# jbr_MDR1901VC1T register map
Registers are 32-bit, access not given, no defined reset value unless marked. A register's access mark holds for its fields unless they carry their own. Addresses are absolute; registers are grouped by the start of their names; [hi:lo] are bit positions; {n}, {i} and the like mark numbered series.

## UART3
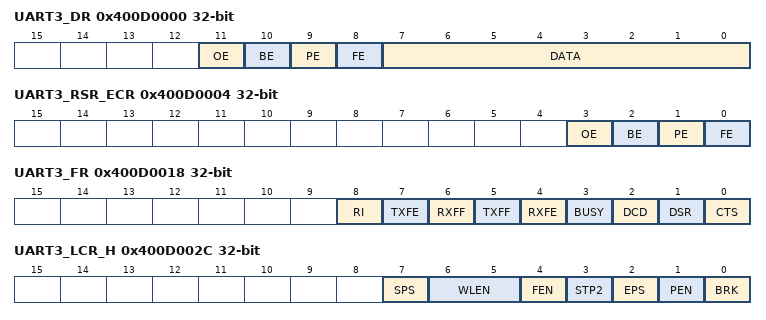
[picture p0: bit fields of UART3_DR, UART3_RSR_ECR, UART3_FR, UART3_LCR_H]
0x400D0000 UART3_DR
  [11] OE, [10] BE, [9] PE, [8] FE, [7:0] DATA
0x400D0004 UART3_RSR_ECR
  [3] OE, [2] BE, [1] PE, [0] FE
0x400D0018 UART3_FR
  [8] RI, [7] TXFE, [6] RXFF, [5] TXFF, [4] RXFE, [3] BUSY, [2] DCD, [1] DSR, [0] CTS
0x400D0020 UART3_ILPR
  [7:0] ILPDVSR
0x400D0024 UART3_IBRD
  [15:0] BAUD_DIVINT
0x400D0028 UART3_FBRD
  [5:0] BAUD_DIVFRAC
0x400D002C UART3_LCR_H
  [7] SPS, [6:5] WLEN, [4] FEN, [3] STP2, [2] EPS, [1] PEN, [0] BRK
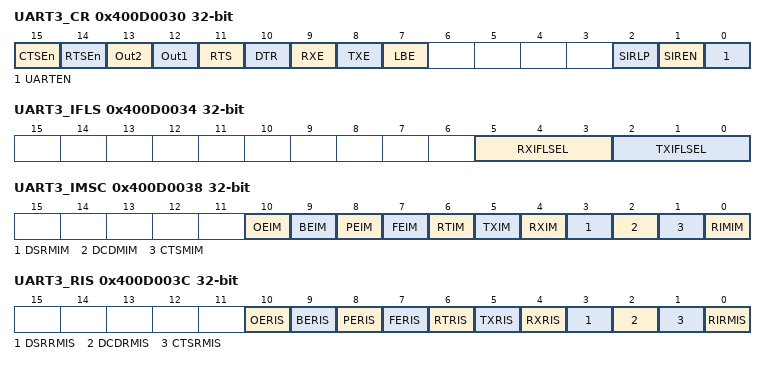
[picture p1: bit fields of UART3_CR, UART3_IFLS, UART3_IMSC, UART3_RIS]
0x400D0030 UART3_CR
  [15] CTSEn, [14] RTSEn, [13] Out2, [12] Out1, [11] RTS, [10] DTR, [9] RXE, [8] TXE, [7] LBE, [2] SIRLP, [1] SIREN, [0] UARTEN
0x400D0034 UART3_IFLS
  [5:3] RXIFLSEL, [2:0] TXIFLSEL
0x400D0038 UART3_IMSC
  [10] OEIM, [9] BEIM, [8] PEIM, [7] FEIM, [6] RTIM, [5] TXIM, [4] RXIM, [3] DSRMIM, [2] DCDMIM, [1] CTSMIM, [0] RIMIM
0x400D003C UART3_RIS
  [10] OERIS, [9] BERIS, [8] PERIS, [7] FERIS, [6] RTRIS, [5] TXRIS, [4] RXRIS, [3] DSRRMIS, [2] DCDRMIS, [1] CTSRMIS, [0] RIRMIS
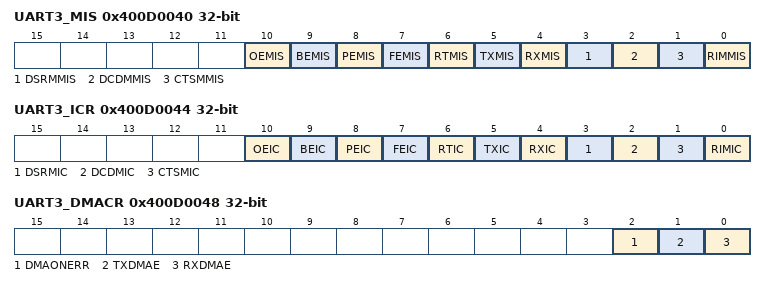
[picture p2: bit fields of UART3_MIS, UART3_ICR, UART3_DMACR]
0x400D0040 UART3_MIS
  [10] OEMIS, [9] BEMIS, [8] PEMIS, [7] FEMIS, [6] RTMIS, [5] TXMIS, [4] RXMIS, [3] DSRMMIS, [2] DCDMMIS, [1] CTSMMIS, [0] RIMMIS
0x400D0044 UART3_ICR
  [10] OEIC, [9] BEIC, [8] PEIC, [7] FEIC, [6] RTIC, [5] TXIC, [4] RXIC, [3] DSRMIC, [2] DCDMIC, [1] CTSMIC, [0] RIMIC
0x400D0048 UART3_DMACR
  [2] DMAONERR, [1] TXDMAE, [0] RXDMAE

## TIMER1
0x40070000 TIMER1_CNT
  [15:0] CNT
0x40070004 TIMER1_PSG
  [15:0] PSG
0x40070008 TIMER1_ARR
  [15:0] ARR
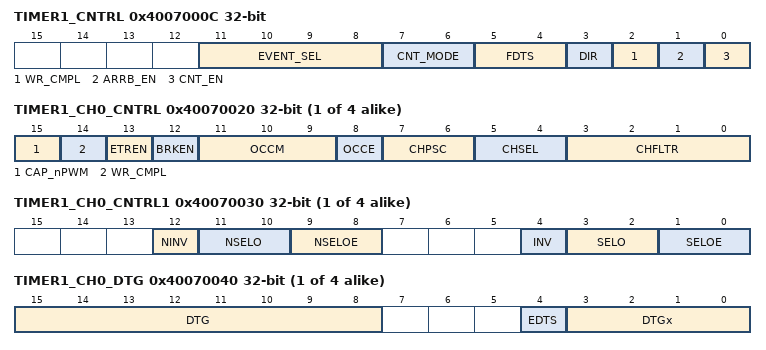
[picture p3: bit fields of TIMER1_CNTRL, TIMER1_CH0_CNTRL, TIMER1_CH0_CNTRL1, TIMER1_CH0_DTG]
0x4007000C TIMER1_CNTRL
  [11:8] EVENT_SEL, [7:6] CNT_MODE, [5:4] FDTS, [3] DIR, [2] WR_CMPL, [1] ARRB_EN, [0] CNT_EN
0x40070010 TIMER1_CCR0
  [15:0] CCR
0x40070014 TIMER1_CCR1
  [15:0] CCR
0x40070018 TIMER1_CCR2
  [15:0] CCR
0x4007001C TIMER1_CCR3
  [15:0] CCR
{0x40070020+4i} TIMER1_CH{i}_CNTRL (i=0..3)
  [15] CAP_nPWM, [14] WR_CMPL, [13] ETREN, [12] BRKEN, [11:9] OCCM, [8] OCCE, [7:6] CHPSC, [5:4] CHSEL, [3:0] CHFLTR
{0x40070030+4i} TIMER1_CH{i}_CNTRL1 (i=0..3)
  [12] NINV, [11:10] NSELO, [9:8] NSELOE, [4] INV, [3:2] SELO, [1:0] SELOE
{0x40070040+4i} TIMER1_CH{i}_DTG (i=0..3)
  [15:8] DTG, [4] EDTS, [3:0] DTGx
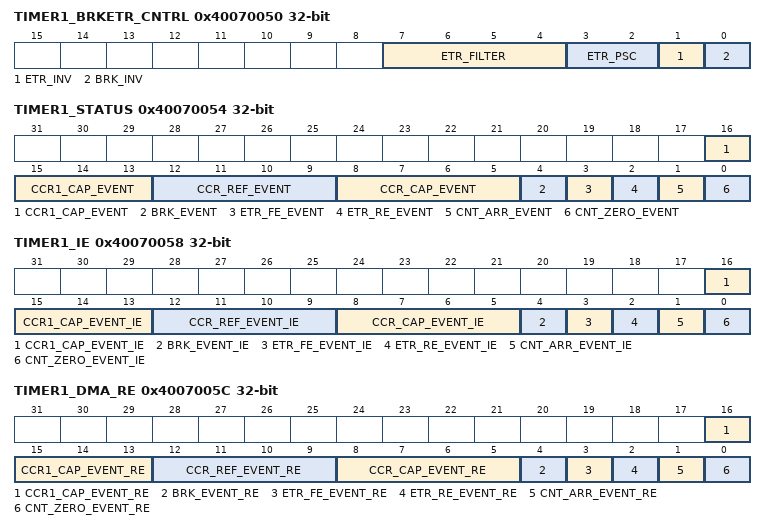
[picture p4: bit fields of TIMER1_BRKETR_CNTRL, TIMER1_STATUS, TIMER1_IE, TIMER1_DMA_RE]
0x40070050 TIMER1_BRKETR_CNTRL
  [7:4] ETR_FILTER, [3:2] ETR_PSC, [1] ETR_INV, [0] BRK_INV
0x40070054 TIMER1_STATUS
  [16:13] CCR1_CAP_EVENT, [12:9] CCR_REF_EVENT, [8:5] CCR_CAP_EVENT, [4] BRK_EVENT, [3] ETR_FE_EVENT, [2] ETR_RE_EVENT, [1] CNT_ARR_EVENT, [0] CNT_ZERO_EVENT
0x40070058 TIMER1_IE
  [16:13] CCR1_CAP_EVENT_IE, [12:9] CCR_REF_EVENT_IE, [8:5] CCR_CAP_EVENT_IE, [4] BRK_EVENT_IE, [3] ETR_FE_EVENT_IE, [2] ETR_RE_EVENT_IE, [1] CNT_ARR_EVENT_IE, [0] CNT_ZERO_EVENT_IE
0x4007005C TIMER1_DMA_RE
  [16:13] CCR1_CAP_EVENT_RE, [12:9] CCR_REF_EVENT_RE, [8:5] CCR_CAP_EVENT_RE, [4] BRK_EVENT_RE, [3] ETR_FE_EVENT_RE, [2] ETR_RE_EVENT_RE, [1] CNT_ARR_EVENT_RE, [0] CNT_ZERO_EVENT_RE
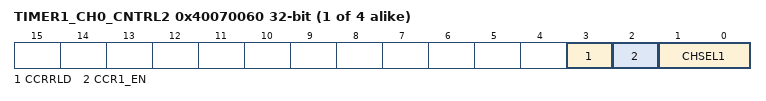
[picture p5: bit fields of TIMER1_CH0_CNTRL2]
{0x40070060+4i} TIMER1_CH{i}_CNTRL2 (i=0..3)
  [3] CCRRLD, [2] CCR1_EN, [1:0] CHSEL1
0x40070070 TIMER1_CCR01
  [15:0] CCR
0x40070074 TIMER1_CCR11
  [15:0] CCR
0x40070078 TIMER1_CCR21
  [15:0] CCR
0x4007007C TIMER1_CCR31
  [15:0] CCR

## TIMER2
0x40078000 TIMER2_CNT
  [15:0] CNT
0x40078004 TIMER2_PSG
  [15:0] PSG
0x40078008 TIMER2_ARR
  [15:0] ARR
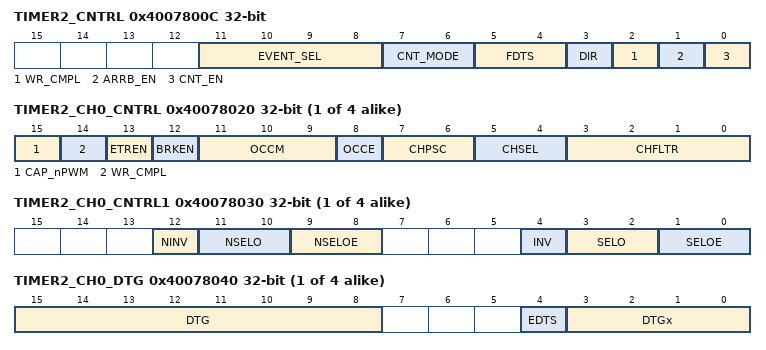
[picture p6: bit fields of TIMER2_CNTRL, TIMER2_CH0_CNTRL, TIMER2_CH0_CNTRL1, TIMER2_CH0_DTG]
0x4007800C TIMER2_CNTRL
  [11:8] EVENT_SEL, [7:6] CNT_MODE, [5:4] FDTS, [3] DIR, [2] WR_CMPL, [1] ARRB_EN, [0] CNT_EN
0x40078010 TIMER2_CCR0
  [15:0] CCR
0x40078014 TIMER2_CCR1
  [15:0] CCR
0x40078018 TIMER2_CCR2
  [15:0] CCR
0x4007801C TIMER2_CCR3
  [15:0] CCR
{0x40078020+4i} TIMER2_CH{i}_CNTRL (i=0..3)
  [15] CAP_nPWM, [14] WR_CMPL, [13] ETREN, [12] BRKEN, [11:9] OCCM, [8] OCCE, [7:6] CHPSC, [5:4] CHSEL, [3:0] CHFLTR
{0x40078030+4i} TIMER2_CH{i}_CNTRL1 (i=0..3)
  [12] NINV, [11:10] NSELO, [9:8] NSELOE, [4] INV, [3:2] SELO, [1:0] SELOE
{0x40078040+4i} TIMER2_CH{i}_DTG (i=0..3)
  [15:8] DTG, [4] EDTS, [3:0] DTGx
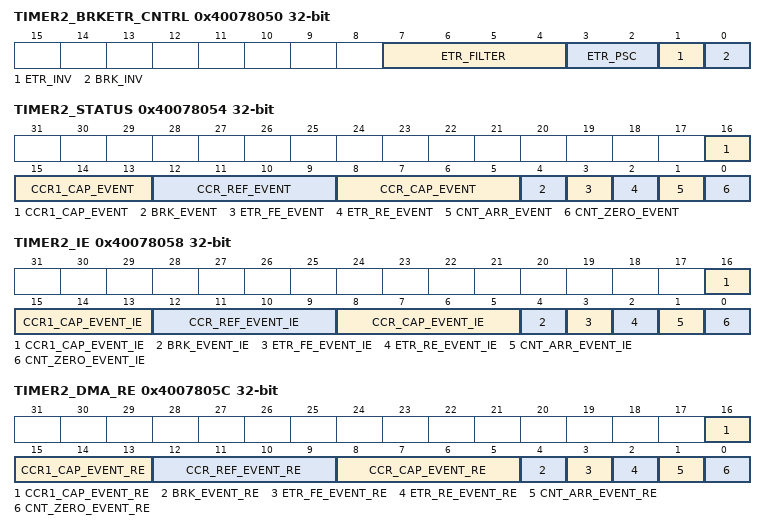
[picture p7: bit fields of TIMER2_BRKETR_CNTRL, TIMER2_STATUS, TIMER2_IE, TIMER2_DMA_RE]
0x40078050 TIMER2_BRKETR_CNTRL
  [7:4] ETR_FILTER, [3:2] ETR_PSC, [1] ETR_INV, [0] BRK_INV
0x40078054 TIMER2_STATUS
  [16:13] CCR1_CAP_EVENT, [12:9] CCR_REF_EVENT, [8:5] CCR_CAP_EVENT, [4] BRK_EVENT, [3] ETR_FE_EVENT, [2] ETR_RE_EVENT, [1] CNT_ARR_EVENT, [0] CNT_ZERO_EVENT
0x40078058 TIMER2_IE
  [16:13] CCR1_CAP_EVENT_IE, [12:9] CCR_REF_EVENT_IE, [8:5] CCR_CAP_EVENT_IE, [4] BRK_EVENT_IE, [3] ETR_FE_EVENT_IE, [2] ETR_RE_EVENT_IE, [1] CNT_ARR_EVENT_IE, [0] CNT_ZERO_EVENT_IE
0x4007805C TIMER2_DMA_RE
  [16:13] CCR1_CAP_EVENT_RE, [12:9] CCR_REF_EVENT_RE, [8:5] CCR_CAP_EVENT_RE, [4] BRK_EVENT_RE, [3] ETR_FE_EVENT_RE, [2] ETR_RE_EVENT_RE, [1] CNT_ARR_EVENT_RE, [0] CNT_ZERO_EVENT_RE
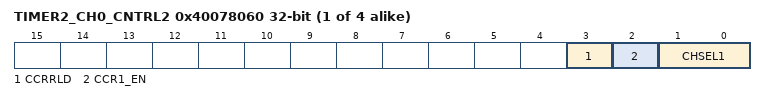
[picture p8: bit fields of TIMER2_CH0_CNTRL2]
{0x40078060+4i} TIMER2_CH{i}_CNTRL2 (i=0..3)
  [3] CCRRLD, [2] CCR1_EN, [1:0] CHSEL1
0x40078070 TIMER2_CCR01
  [15:0] CCR
0x40078074 TIMER2_CCR11
  [15:0] CCR
0x40078078 TIMER2_CCR21
  [15:0] CCR
0x4007807C TIMER2_CCR31
  [15:0] CCR
